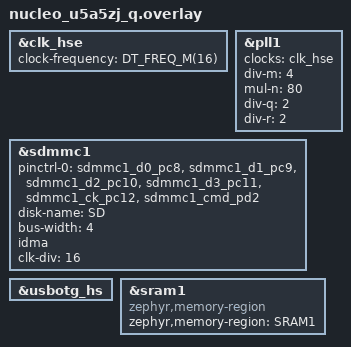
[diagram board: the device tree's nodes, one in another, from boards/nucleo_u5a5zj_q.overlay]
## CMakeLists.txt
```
cmake_minimum_required(VERSION 3.20.0)
find_package(Zephyr REQUIRED HINTS $ENV{ZEPHYR_BASE})
project(usb_msc_sd)

zephyr_linker_sources(DATA_SECTIONS ${CMAKE_CURRENT_SOURCE_DIR}/sram1.ld)

target_sources(app PRIVATE 
    src/main.c
    src/idma_buffer.c
)
```

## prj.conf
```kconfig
CONFIG_MAIN_STACK_SIZE=2048
CONFIG_COMMON_LIBC_MALLOC_ARENA_SIZE=8192
CONFIG_DISK_ACCESS=y
CONFIG_DISK_DRIVERS=y
CONFIG_FILE_SYSTEM=y
CONFIG_FAT_FILESYSTEM_ELM=y
CONFIG_SDMMC_STM32_HWFC=y
CONFIG_HWINFO=y

CONFIG_USB_DEVICE_STACK_NEXT=y
CONFIG_USBD_MSC_CLASS=y
CONFIG_LOG=y
CONFIG_SDMMC_STM32=y
CONFIG_DISK_DRIVER_SDMMC=y
CONFIG_USBD_MSC_LUNS_PER_INSTANCE=1

# Reduce logging for better throughput (DBG logging causes buffer exhaustion)
CONFIG_USBD_MSC_LOG_LEVEL_WRN=y
CONFIG_SDMMC_LOG_LEVEL_WRN=y
CONFIG_DISK_LOG_LEVEL_WRN=y
CONFIG_UDC_DRIVER_LOG_LEVEL_WRN=y

# Larger SCSI buffer for better throughput
CONFIG_USBD_MSC_SCSI_BUFFER_SIZE=4096

# Increase buffer pool to prevent exhaustion during large transfers
CONFIG_UDC_BUF_POOL_SIZE=32768
CONFIG_UDC_BUF_COUNT=64

# Increase MSC thread stack for better performance
CONFIG_USBD_MSC_STACK_SIZE=2048

CONFIG_CACHE_MANAGEMENT=y
CONFIG_DCACHE_LINE_SIZE=32
```

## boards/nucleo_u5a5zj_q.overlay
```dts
/* nucleo_u5a5zj_q.overlay */

&clk_hse {
    status = "okay";
    clock-frequency = <DT_FREQ_M(16)>;
};

&pll1 {
    clocks = <&clk_hse>;
    div-m = <4>;
    mul-n = <80>;
    div-q = <2>;
    div-r = <2>;
    status = "okay";
};

&sdmmc1 {
    status = "okay";
    pinctrl-0 = <&sdmmc1_d0_pc8 &sdmmc1_d1_pc9 &sdmmc1_d2_pc10 &sdmmc1_d3_pc11 &sdmmc1_ck_pc12 &sdmmc1_cmd_pd2>;
    pinctrl-names = "default";
    disk-name = "SD";
    bus-width = <4>;
    idma;
    clk-div = <16>;  /* 160MHz / (16+2) = 8.9MHz - conservative for debugging */
};

&usbotg_hs {
    status = "okay";
};

/* Configure SRAM1 (0x28000000) as a memory region for USB IDMA access */
&sram1 {
    compatible = "zephyr,memory-region", "mmio-sram";
    device_type = "memory";
    zephyr,memory-region = "SRAM1";
};
```

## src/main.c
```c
#include <zephyr/kernel.h>
#include <zephyr/logging/log.h>
#include <zephyr/usb/usbd.h>
#include <zephyr/usb/class/usbd_msc.h>
#include <zephyr/storage/disk_access.h>
#include <zephyr/init.h>
extern uint8_t idma_bounce_buffer[4096];

LOG_MODULE_REGISTER(main, LOG_LEVEL_INF);

#include <zephyr/cache.h>

static int early_disk_init(void)
{
    int err = disk_access_init("SD");
    if (err) {
        LOG_ERR("Early SD init failed: %d", err);
        return err;
    }
    LOG_INF("Early SD init OK");

    extern uint8_t idma_bounce_buffer[4096];
    
    /* Fill with known pattern first */
    memset(idma_bounce_buffer, 0xAA, 512);
    
    int ret = disk_access_read("SD", idma_bounce_buffer, 0, 1);
    LOG_INF("disk_access_read returned: %d", ret);
    
    sys_cache_data_invd_range(idma_bounce_buffer, 512);
    
    /* Check if buffer changed at all */
    bool all_aa = true;
    bool all_zero = true;
    for (int i = 0; i < 512; i++) {
        if (idma_bounce_buffer[i] != 0xAA) all_aa = false;
        if (idma_bounce_buffer[i] != 0x00) all_zero = false;
    }
    LOG_INF("Buffer: all_0xAA=%d, all_zero=%d", all_aa, all_zero);
    
    LOG_HEXDUMP_INF(idma_bounce_buffer, 64, "Sector 0 first 64 bytes:");

    return 0;
}

SYS_INIT(early_disk_init, APPLICATION, CONFIG_APPLICATION_INIT_PRIORITY);

USBD_DEVICE_DEFINE(my_usbd, DEVICE_DT_GET(DT_NODELABEL(usbotg_hs)),
                   0x2fe3, 0x0001);

USBD_DESC_LANG_DEFINE(my_lang);
USBD_DESC_MANUFACTURER_DEFINE(my_mfr, "Joost");
USBD_DESC_PRODUCT_DEFINE(my_product, "SD Card");
USBD_DESC_SERIAL_NUMBER_DEFINE(my_sn);

/* Configuration string descriptors - required for proper enumeration */
USBD_DESC_CONFIG_DEFINE(my_fs_cfg_desc, "FS Configuration");
USBD_DESC_CONFIG_DEFINE(my_hs_cfg_desc, "HS Configuration");

USBD_CONFIGURATION_DEFINE(my_fs_config, USB_SCD_SELF_POWERED, 200, &my_fs_cfg_desc);
USBD_CONFIGURATION_DEFINE(my_hs_config, USB_SCD_SELF_POWERED, 200, &my_hs_cfg_desc);

/* MSC LUN: vendor=8 chars, product=16 chars exactly */
USBD_DEFINE_MSC_LUN(sd_lun, "SD", "Joost   ", "SD Card         ", "1.0");

int main(void)
{
    int err;
    int status;
    printk("BOUNCE BUFFER @ %p\n", (void*)idma_bounce_buffer);
    // ... rest of main
    LOG_INF("USB MSC SD starting");

    status = disk_access_status("SD");
    LOG_INF("Disk status in main: %d (0=OK, 1=UNINIT, 2=NOMEDIA)", status);

    /* Add string descriptors */
    usbd_add_descriptor(&my_usbd, &my_lang);
    usbd_add_descriptor(&my_usbd, &my_mfr);
    usbd_add_descriptor(&my_usbd, &my_product);
    usbd_add_descriptor(&my_usbd, &my_sn);

    /* Check for High-Speed capability and add HS config first if supported */
    if (usbd_caps_speed(&my_usbd) == USBD_SPEED_HS) {
        err = usbd_add_configuration(&my_usbd, USBD_SPEED_HS, &my_hs_config);
        if (err) {
            LOG_ERR("Failed to add HS configuration: %d", err);
            return err;
        }
        err = usbd_register_all_classes(&my_usbd, USBD_SPEED_HS, 1, NULL);
        if (err) {
            LOG_ERR("Failed to register HS classes: %d", err);
            return err;
        }
        LOG_INF("High-Speed configuration added");
    }

    /* Always add Full-Speed configuration */
    err = usbd_add_configuration(&my_usbd, USBD_SPEED_FS, &my_fs_config);
    if (err) {
        LOG_ERR("Failed to add FS configuration: %d", err);
        return err;
    }
    err = usbd_register_all_classes(&my_usbd, USBD_SPEED_FS, 1, NULL);
    if (err) {
        LOG_ERR("Failed to register FS classes: %d", err);
        return err;
    }

    err = usbd_init(&my_usbd);
    if (err) {
        LOG_ERR("USB init failed: %d", err);
        return err;
    }

    err = usbd_enable(&my_usbd);
    if (err) {
        LOG_ERR("USB enable failed: %d", err);
        return err;
    }

    LOG_INF("USB MSC ready");

    while (1) {
        k_sleep(K_SECONDS(5));
        status = disk_access_status("SD");
        LOG_INF("Disk status: %d", status);
    }

    return 0;
}
```

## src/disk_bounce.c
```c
/* bounce_disk.c - Wrapper to handle IDMA buffer requirements */

#include <zephyr/kernel.h>
#include <zephyr/storage/disk_access.h>
#include <zephyr/logging/log.h>
#include <string.h>

LOG_MODULE_REGISTER(bounce_disk, LOG_LEVEL_INF);

/* 4KB bounce buffer in SRAM1 */
__attribute__((section(".sram1_data")))
__aligned(32)
static uint8_t idma_bounce[4096];

#define SECTOR_SIZE 512
#define BOUNCE_SECTORS (sizeof(idma_bounce) / SECTOR_SIZE)

static bool addr_needs_bounce(const void *addr)
{
    uintptr_t a = (uintptr_t)addr;
    /* SRAM1/2 range on STM32U5 - IDMA can access this */
    if (a >= 0x28000000 && a < 0x28100000) {
        return false;
    }
    /* Everything else needs bounce buffer */
    return true;
}

int bounce_disk_read(const char *name, uint8_t *buf, uint32_t sector, uint32_t count)
{
    int ret;
    
    if (!addr_needs_bounce(buf)) {
        return disk_access_read(name, buf, sector, count);
    }
    
    LOG_DBG("Bounce read: sector %u, count %u", sector, count);
    
    while (count > 0) {
        uint32_t chunk = MIN(count, BOUNCE_SECTORS);
        
        ret = disk_access_read(name, idma_bounce, sector, chunk);
        if (ret != 0) {
            return ret;
        }
        
        memcpy(buf, idma_bounce, chunk * SECTOR_SIZE);
        
        buf += chunk * SECTOR_SIZE;
        sector += chunk;
        count -= chunk;
    }
    
    return 0;
}

int bounce_disk_write(const char *name, const uint8_t *buf, uint32_t sector, uint32_t count)
{
    int ret;
    
    if (!addr_needs_bounce(buf)) {
        return disk_access_write(name, buf, sector, count);
    }
    
    LOG_DBG("Bounce write: sector %u, count %u", sector, count);
    
    while (count > 0) {
        uint32_t chunk = MIN(count, BOUNCE_SECTORS);
        
        memcpy(idma_bounce, buf, chunk * SECTOR_SIZE);
        
        ret = disk_access_write(name, idma_bounce, sector, chunk);
        if (ret != 0) {
            return ret;
        }
        
        buf += chunk * SECTOR_SIZE;
        sector += chunk;
        count -= chunk;
    }
    
    return 0;
}
```

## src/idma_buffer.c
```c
#include <zephyr/kernel.h>

__attribute__((section(".sram1_data")))
__aligned(32)
uint8_t idma_bounce_buffer[4096];
```

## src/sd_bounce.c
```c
#include <zephyr/kernel.h>
#include <zephyr/storage/disk_access.h>
#include <string.h>

extern uint8_t idma_bounce_buffer[4096];

int sd_bounce_read(const char *disk, uint8_t *dst, uint32_t sector, uint32_t count)
{
    int ret;
    uint32_t sector_size = 512;
    
    while (count > 0) {
        uint32_t chunk = MIN(count, sizeof(idma_bounce_buffer) / sector_size);
        
        ret = disk_access_read(disk, idma_bounce_buffer, sector, chunk);
        if (ret != 0) return ret;
        
        memcpy(dst, idma_bounce_buffer, chunk * sector_size);
        
        dst += chunk * sector_size;
        sector += chunk;
        count -= chunk;
    }
    return 0;
}

int sd_bounce_write(const char *disk, const uint8_t *src, uint32_t sector, uint32_t count)
{
    int ret;
    uint32_t sector_size = 512;
    
    while (count > 0) {
        uint32_t chunk = MIN(count, sizeof(idma_bounce_buffer) / sector_size);
        
        memcpy(idma_bounce_buffer, src, chunk * sector_size);
        
        ret = disk_access_write(disk, idma_bounce_buffer, sector, chunk);
        if (ret != 0) return ret;
        
        src += chunk * sector_size;
        sector += chunk;
        count -= chunk;
    }
    return 0;
}
```
